AUTOSAR XML (schema 4-2-2)
package /ComponentTypes
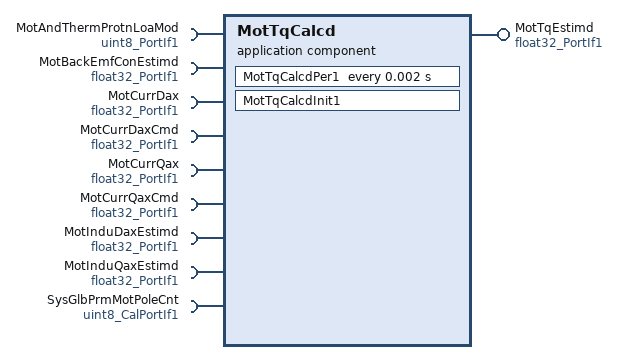
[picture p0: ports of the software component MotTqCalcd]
  application sw component type MotTqCalcd  # This component calculates motor torque estimate from measured Motor Currents or reference MotorCurrents based on the Motor Control And Thermal Protection LOA Mode
    provide port MotTqEstimd: nonqueued-sender-com-spec{data-element=Val, init-value=0}, provided-interface=float32_PortIf1  # Motor Torque Estimated
    9 x require port:
      MotAndThermProtnLoaMod: nonqueued-receiver-com-spec{data-element=Val, filter=data-filter-type=ALWAYS, init-value=0}, required-interface=uint8_PortIf1  # Motor And Thermal LOA Mode On - is a bit pack with respect to different LOA state and we don't trust current measurement in any of this state
      MotBackEmfConEstimd: nonqueued-receiver-com-spec{data-element=Val, filter=data-filter-type=ALWAYS, init-value=0.025}, required-interface=float32_PortIf1  # Motor Back EMF Constant Estimated
      MotCurrDax: nonqueued-receiver-com-spec{data-element=Val, filter=data-filter-type=ALWAYS, init-value=0}, required-interface=float32_PortIf1  # D axis Measured Motor Current
      MotCurrDaxCmd: nonqueued-receiver-com-spec{data-element=Val, filter=data-filter-type=ALWAYS, init-value=0}, required-interface=float32_PortIf1  # D Axis Motor Current Reference
      MotCurrQax: nonqueued-receiver-com-spec{data-element=Val, filter=data-filter-type=ALWAYS, init-value=0}, required-interface=float32_PortIf1  # Q axis Measured Motor Current
      MotCurrQaxCmd: nonqueued-receiver-com-spec{data-element=Val, filter=data-filter-type=ALWAYS, init-value=0}, required-interface=float32_PortIf1  # Q Axis Motor Current Reference
      MotInduDaxEstimd: nonqueued-receiver-com-spec{data-element=Val, filter=data-filter-type=ALWAYS, init-value=0.00011889}, required-interface=float32_PortIf1  # Estimated D Axis Motor Inductance
      MotInduQaxEstimd: nonqueued-receiver-com-spec{data-element=Val, filter=data-filter-type=ALWAYS, init-value=0.00011889}, required-interface=float32_PortIf1  # Estimated Q Axis Motor Inductance
      SysGlbPrmMotPoleCnt: parameter-require-com-spec{init-value=8, parameter=Val}, required-interface=uint8_CalPortIf1
    behavior MotTqCalcd_InternalBehavior: port-api-option{enable-take-address=false, error-handling=NO-TRANSFORMER-ERROR-HANDLING, indirect-api=false, port=SysGlbPrmMotPoleCnt}
      init event MotTqCalcd_InitEvent: start-on-event=MotTqCalcdInit1
      timing event TMT_MotTqCalcdPer1: start-on-event=MotTqCalcdPer1, period=0.002
      runnable MotTqCalcdInit1  # Initialization Runnable
      runnable MotTqCalcdPer1  # Periodic Runnable at 2 milli-seconds
        data-receive-point-by-arguments:
          8 x access:
            REC_MotAndThermProtnLoaMod_Val: accessed-variable=MotAndThermProtnLoaMod.Val
            REC_MotBackEmfConEstimd_Val: accessed-variable=MotBackEmfConEstimd.Val
            REC_MotCurrDax_Val: accessed-variable=MotCurrDax.Val
            REC_MotCurrDaxCmd_Val: accessed-variable=MotCurrDaxCmd.Val
            REC_MotCurrQax_Val: accessed-variable=MotCurrQax.Val
            REC_MotCurrQaxCmd_Val: accessed-variable=MotCurrQaxCmd.Val
            REC_MotInduDaxEstimd_Val: accessed-variable=MotInduDaxEstimd.Val
            REC_MotInduQaxEstimd_Val: accessed-variable=MotInduQaxEstimd.Val
        data-send-points:
          access SEND_MotTqEstimd_Val: accessed-variable=MotTqEstimd.Val
  swc implementation MotTqCalcd_Implementation: behavior=MotTqCalcd_InternalBehavior
    code-descriptors:
      code Default: artifact-descriptors=autosar-engineering-object={short-label=Default, category=SWSRC}
